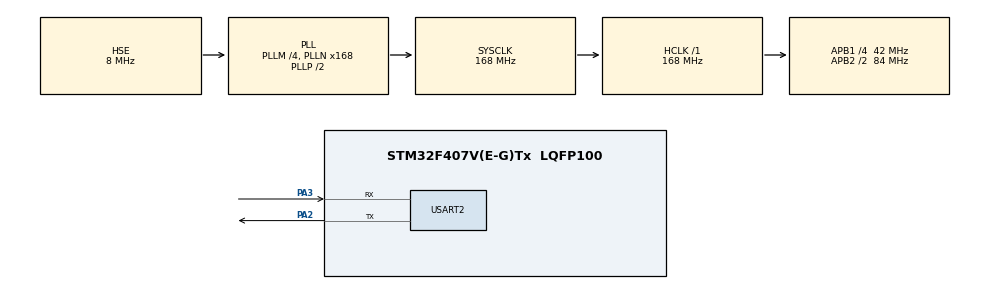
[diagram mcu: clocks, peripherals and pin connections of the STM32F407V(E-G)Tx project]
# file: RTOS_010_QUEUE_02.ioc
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Mcu.Family=STM32F4
RCC.PLLSourceVirtual=RCC_PLLSOURCE_HSE
VP_SYS_VS_tim6.Mode=TIM6
PH0-OSC_IN.Signal=RCC_OSC_IN
RCC.CortexFreq_Value=168000000
FREERTOS.Tasks01=defaultTask,0,128,StartDefaultTask,Default,NULL,Dynamic,NULL,NULL
NVIC.TIM6_DAC_IRQn=true\:0\:0\:false\:false\:true\:false\:false\:true
RCC.APB1CLKDivider=RCC_HCLK_DIV4
RCC.SYSCLKSource=RCC_SYSCLKSOURCE_PLLCLK
ProjectManager.StackSize=0x400
PA3.Mode=Asynchronous
ProjectManager.TargetToolchain=STM32CubeIDE
RCC.HCLKFreq_Value=168000000
RCC.APB2TimFreq_Value=168000000
RCC.LSE_VALUE=32768
RCC.AHBFreq_Value=168000000
PH0-OSC_IN.Mode=HSE-External-Oscillator
RCC.HSE_VALUE=8000000
board=custom
RCC.VCOOutputFreq_Value=336000000
RCC.APB2Freq_Value=84000000
PH1-OSC_OUT.Signal=RCC_OSC_OUT
VP_FREERTOS_VS_CMSIS_V1.Mode=CMSIS_V1
Mcu.Name=STM32F407V(E-G)Tx
PA2.Signal=USART2_TX
PH1-OSC_OUT.Mode=HSE-External-Oscillator
RCC.48MHZClocksFreq_Value=84000000
RCC.SYSCLKFreq_VALUE=168000000
Mcu.Package=LQFP100
NVIC.TimeBase=TIM6_DAC_IRQn
USART2.VirtualMode=VM_ASYNC
NVIC.TimeBaseIP=TIM6
ProjectManager.HeapSize=0x200
RCC.HSI_VALUE=16000000
NVIC.PriorityGroup=NVIC_PRIORITYGROUP_4
RCC.APB2CLKDivider=RCC_HCLK_DIV2
RCC.PLLM=4
RCC.PLLN=168
RCC.APB1TimFreq_Value=84000000
PA2.Mode=Asynchronous
RCC.APB1Freq_Value=42000000
PA3.Signal=USART2_RX

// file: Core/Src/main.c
/* USER CODE BEGIN Header */
/**
  ******************************************************************************
  * @file           : main.c
  * @brief          : Main program body
  ******************************************************************************
  * @attention
  *
  * <h2><center>&copy; Copyright (c) 2022 STMicroelectronics.
  * All rights reserved.</center></h2>
  *
  * This software component is licensed by ST under BSD 3-Clause license,
  * the "License"; You may not use this file except in compliance with the
  * License. You may obtain a copy of the License at:
  *                        opensource.org/licenses/BSD-3-Clause
  *
  ******************************************************************************
  */
/* USER CODE END Header */
#include "main.h"
#include "cmsis_os.h"

/* USER CODE BEGIN Includes */
#include "FreeRTOS.h"
#include "task.h"
#include "queue.h"
#include "string.h"
#include "stdio.h"
/* USER CODE END Includes */

UART_HandleTypeDef huart2;

void SystemClock_Config(void);
static void MX_GPIO_Init(void);
static void MX_USART2_UART_Init(void);

/* USER CODE BEGIN 0 */

/* ************************* TASK HANDLE ****************************** */
TaskHandle_t Task1Handle;
TaskHandle_t Task2Handle;
TaskHandle_t ReceiverTask;

/* ************************* TASK FUNCTION *************************** */
void TASK1_CONTROL(void *params);
void TASK2_CONTROL(void *params);
void RECEIVER_TASK(void *params);

/* ************************* QUEUE HANDLE ***************************** */
QueueHandle_t SimpleQueue;

/* ************************ STRUCTURE DEFINATION ********************** */
typedef struct
{
	char *str;
	int counter;
	uint16_t largeValue;
}myStruct;

int index1;
int index2;
/* USER CODE END 0 */

int main(void)
{

  /* MCU Configuration--------------------------------------------------------*/

  /* Reset of all peripherals, Initializes the Flash interface and the Systick. */
  HAL_Init();

  /* Configure the system clock */
  SystemClock_Config();

  /* Initialize all configured peripherals */
  MX_GPIO_Init();
  MX_USART2_UART_Init();
  /* USER CODE BEGIN 2 */

  /* ************************** CREATE QUEUE ************************* */
  SimpleQueue = xQueueCreate(2,sizeof(myStruct));

  if(SimpleQueue != NULL)
  {
	  char *str = "Structure Queue Created Successfully\n\n";
	  HAL_UART_Transmit(&huart2, (uint8_t *)str, strlen(str), HAL_MAX_DELAY);
  }
  if(SimpleQueue == NULL)
  {
	  char *str = "Unable to create Structure Queue\n\n";
	  HAL_UART_Transmit(&huart2, (uint8_t *)str, strlen(str), HAL_MAX_DELAY);

  }

  /* ********************* CREATE TASK ****************************** */
  xTaskCreate(TASK1_CONTROL, "Task1", configMINIMAL_STACK_SIZE, NULL, 2, &Task1Handle);
  xTaskCreate(TASK2_CONTROL, "Task2", configMINIMAL_STACK_SIZE, NULL, 2, &Task2Handle);
  xTaskCreate(RECEIVER_TASK, "Task3", configMINIMAL_STACK_SIZE, NULL, 1, &ReceiverTask);

  /* ********************* SCHEDULER ******************************* */
  vTaskStartScheduler();

  /* We should never get here as control is now taken by the scheduler */
  /* Infinite loop */
  while (1)
  {

  }
}

void SystemClock_Config(void)
{
  RCC_OscInitTypeDef RCC_OscInitStruct = {0};
  RCC_ClkInitTypeDef RCC_ClkInitStruct = {0};

  /** Configure the main internal regulator output voltage
  */
  __HAL_RCC_PWR_CLK_ENABLE();
  __HAL_PWR_VOLTAGESCALING_CONFIG(PWR_REGULATOR_VOLTAGE_SCALE1);
  /** Initializes the RCC Oscillators according to the specified parameters
  * in the RCC_OscInitTypeDef structure.
  */
  RCC_OscInitStruct.OscillatorType = RCC_OSCILLATORTYPE_HSE;
  RCC_OscInitStruct.HSEState = RCC_HSE_ON;
  RCC_OscInitStruct.PLL.PLLState = RCC_PLL_ON;
  RCC_OscInitStruct.PLL.PLLSource = RCC_PLLSOURCE_HSE;
  RCC_OscInitStruct.PLL.PLLM = 4;
  RCC_OscInitStruct.PLL.PLLN = 168;
  RCC_OscInitStruct.PLL.PLLP = RCC_PLLP_DIV2;
  RCC_OscInitStruct.PLL.PLLQ = 4;
  if (HAL_RCC_OscConfig(&RCC_OscInitStruct) != HAL_OK)
  {
    Error_Handler();
  }
  /** Initializes the CPU, AHB and APB buses clocks
  */
  RCC_ClkInitStruct.ClockType = RCC_CLOCKTYPE_HCLK|RCC_CLOCKTYPE_SYSCLK
                              |RCC_CLOCKTYPE_PCLK1|RCC_CLOCKTYPE_PCLK2;
  RCC_ClkInitStruct.SYSCLKSource = RCC_SYSCLKSOURCE_PLLCLK;
  RCC_ClkInitStruct.AHBCLKDivider = RCC_SYSCLK_DIV1;
  RCC_ClkInitStruct.APB1CLKDivider = RCC_HCLK_DIV4;
  RCC_ClkInitStruct.APB2CLKDivider = RCC_HCLK_DIV2;

  if (HAL_RCC_ClockConfig(&RCC_ClkInitStruct, FLASH_LATENCY_5) != HAL_OK)
  {
    Error_Handler();
  }
}

static void MX_USART2_UART_Init(void)
{

  huart2.Instance = USART2;
  huart2.Init.BaudRate = 115200;
  huart2.Init.WordLength = UART_WORDLENGTH_8B;
  huart2.Init.StopBits = UART_STOPBITS_1;
  huart2.Init.Parity = UART_PARITY_NONE;
  huart2.Init.Mode = UART_MODE_TX_RX;
  huart2.Init.HwFlowCtl = UART_HWCONTROL_NONE;
  huart2.Init.OverSampling = UART_OVERSAMPLING_16;
  if (HAL_UART_Init(&huart2) != HAL_OK)
  {
    Error_Handler();
  }

}

static void MX_GPIO_Init(void)
{

  /* GPIO Ports Clock Enable */
  __HAL_RCC_GPIOH_CLK_ENABLE();
  __HAL_RCC_GPIOA_CLK_ENABLE();

}

/* USER CODE BEGIN 4 */
void TASK1_CONTROL(void *params)
{
	myStruct *ptrtostruct;
	uint32_t tickDelay = pdMS_TO_TICKS(2000);
	for(;;)
	{
		char *str = "Entered TASK1- about send data to queue\n\n";
		HAL_UART_Transmit(&huart2, (uint8_t *)str, strlen(str), HAL_MAX_DELAY);

		/* ******************* ALLOCATE MEMORY TO THE PTR *********************** */
		ptrtostruct = pvPortMalloc(sizeof(myStruct));

		/* ******************* LOAD DATA TO STRUCTURE ************************** */
		ptrtostruct->counter = 1 + index1;
		ptrtostruct->largeValue = 1000 + index1 *100;
		ptrtostruct->str = "Hello From Task1\n";

		/* ******************* SEND DATA TO QUEUE ***************************** */

		if (xQueueSend(SimpleQueue,&ptrtostruct,portMAX_DELAY) == pdPASS)
		{
			char *str2 = "Successfully sent data to the queue\nLeaving Task1\n\n";
			HAL_UART_Transmit(&huart2, (uint8_t *)str2, strlen(str2), HAL_MAX_DELAY);
		}
		index1 = index1 + 1;

		vTaskDelay(tickDelay);
	}
}

void TASK2_CONTROL(void *params)
{
	myStruct *ptrtostruct;
	uint32_t tickDelay = pdMS_TO_TICKS(2000);
	for(;;)
	{
		char *str = "Entered TASK2- about send data to queue\n\n";
		HAL_UART_Transmit(&huart2, (uint8_t *)str, strlen(str), HAL_MAX_DELAY);

		/* ******************* ALLOCATE MEMORY TO THE PTR *********************** */
		ptrtostruct = pvPortMalloc(sizeof(myStruct));

		/* ******************* LOAD DATA TO STRUCTURE ************************** */
		ptrtostruct->counter = 1 + index2;
		ptrtostruct->largeValue = 2000 + index1 *200;
		ptrtostruct->str = "Hello From Task2\n";

		/* ******************* SEND DATA TO QUEUE ***************************** */

		if (xQueueSend(SimpleQueue,&ptrtostruct,portMAX_DELAY) == pdPASS)
		{
			char *str2 = "Successfully sent data to the queue\nLeaving Task1\n\n";
			HAL_UART_Transmit(&huart2, (uint8_t *)str2, strlen(str2), HAL_MAX_DELAY);
		}
		index2 = index2 + 1;

		vTaskDelay(tickDelay);
	}
}
void RECEIVER_TASK(void *params)
{
	myStruct *Rptrtostruct;
	uint32_t tickDelay = pdMS_TO_TICKS(3000);
	char *ptr;
	for(;;)
	{
		char *chr = "Entered RECEIVER TASK - about receive data from queue";
		HAL_UART_Transmit(&huart2, (uint8_t *)chr, strlen(chr), HAL_MAX_DELAY);

		/* ********************* RECEIVE FROM QUEUE ************************ */
		if(xQueueReceive(SimpleQueue, &Rptrtostruct, portMAX_DELAY) == pdPASS)
		{
			ptr = pvPortMalloc(100 * sizeof(char)); /* allocate memory for string */

			sprintf(ptr,"Received from Queue\nCounter = %d\nLarge Value = %u\nString = %s\n\n\n",Rptrtostruct->counter,
					Rptrtostruct->largeValue,Rptrtostruct->str);
			HAL_UART_Transmit(&huart2, (uint8_t *)ptr, strlen(ptr), HAL_MAX_DELAY);

			vPortFree(ptr); /* String Memory */
		}
		vPortFree(Rptrtostruct); /* free the structure memory */
		vTaskDelay(tickDelay);
	}
}
/* USER CODE END 4 */

 /**
  * @brief  Period elapsed callback in non blocking mode
  * @note   This function is called  when TIM6 interrupt took place, inside
  * HAL_TIM_IRQHandler(). It makes a direct call to HAL_IncTick() to increment
  * a global variable "uwTick" used as application time base.
  * @param  htim : TIM handle
  * @retval None
  */
void HAL_TIM_PeriodElapsedCallback(TIM_HandleTypeDef *htim)
{
  if (htim->Instance == TIM6) {
    HAL_IncTick();
  }
}

void Error_Handler(void)
{
  __disable_irq();
  while (1)
  {
  }
}

/************************ (C) COPYRIGHT STMicroelectronics *****END OF FILE****/
